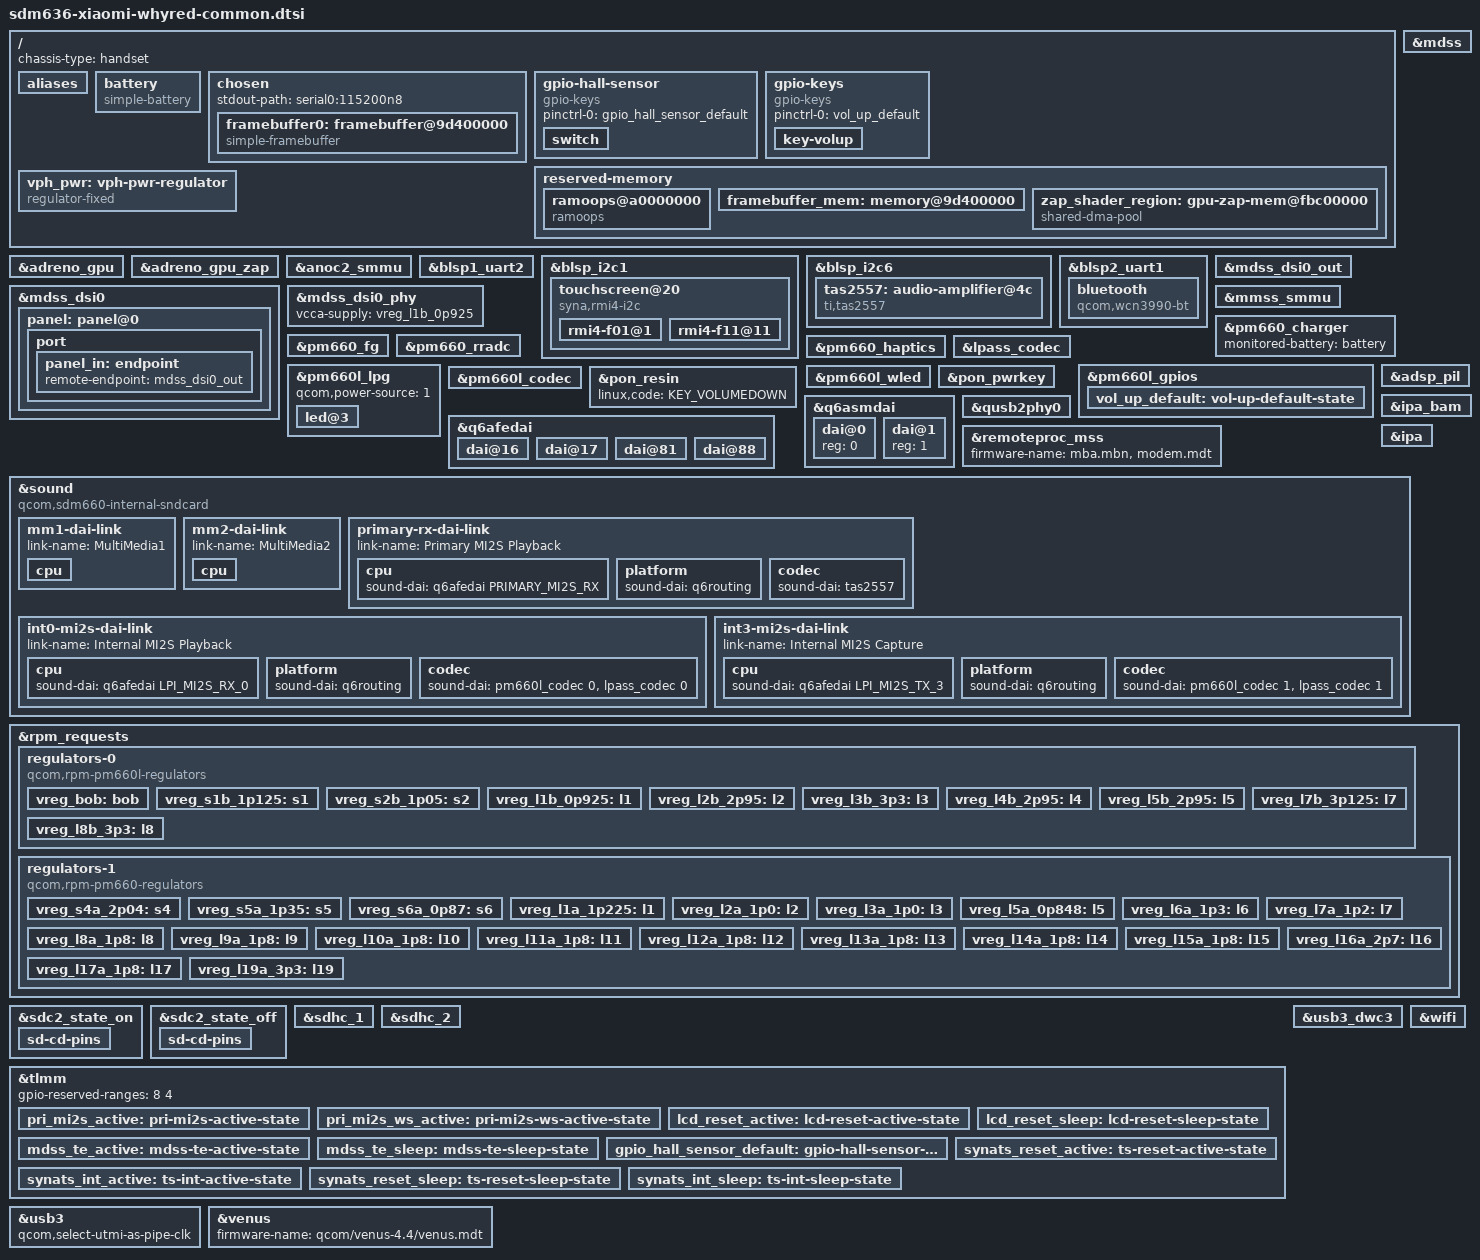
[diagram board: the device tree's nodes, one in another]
// SPDX-License-Identifier: BSD-3-Clause
// SPDX-FileCopyrightText: 2025 Mathesh Velayudan <123v.mathesh@gmail.com>
// SPDX-FileCopyrightText: 2025 Alexey Minnekhanov <alexeymin@postmarketos.org>
// SPDX-FileCopyrightText: 2026 RVC11 <membermadde.insiddev25120@hotmail.com>

/dts-v1/;

#include "sdm636.dtsi"
#include "pm660.dtsi"
#include "pm660l.dtsi"
#include <dt-bindings/gpio/gpio.h>
#include <dt-bindings/input/input.h>
#include <dt-bindings/input/gpio-keys.h>
#include <dt-bindings/leds/common.h>
#include <dt-bindings/pinctrl/qcom,pmic-gpio.h>
#include <dt-bindings/sound/qcom,q6afe.h>
#include <dt-bindings/sound/qcom,q6asm.h>

/delete-node/ &zap_shader_region;

/ {
	chassis-type = "handset";

	aliases {
		serial0 = &blsp1_uart2;
		serial1 = &blsp2_uart1;
	};

	battery: battery {
		compatible = "simple-battery";

		charge-full-design-microamp-hours = <4000000>;
		voltage-min-design-microvolt = <3400000>;
		voltage-max-design-microvolt = <4408000>;
	};

	chosen {
		#address-cells = <2>;
		#size-cells = <2>;
		ranges;

		stdout-path = "serial0:115200n8";

		framebuffer0: framebuffer@9d400000 {
			compatible = "simple-framebuffer";
			reg = <0 0x9d400000 0x0 (1080 * 2160 * 4)>;
			width = <1080>;
			height = <2160>;
			stride = <(1080 * 4)>;
			format = "a8r8g8b8";

			assigned-clocks = <&mmcc MDSS_MDP_CLK>,
				<&mmcc MDSS_VSYNC_CLK>;
			assigned-clock-rates = <300000000>,
				<19200000>;
			clocks = <&mmcc MDSS_AHB_CLK>,
				<&mmcc MDSS_AXI_CLK>,
				<&mmcc MDSS_VSYNC_CLK>,
				<&mmcc MDSS_MDP_CLK>,
				<&mmcc BYTE0_CLK_SRC>,
				<&mmcc PCLK0_CLK_SRC>,
				<&mmcc MDSS_BYTE0_CLK>,
				<&mmcc MDSS_BYTE0_INTF_CLK>,
				<&mmcc MNOC_AHB_CLK>,
				<&mmcc MISC_AHB_CLK>,
				<&mmcc MDSS_PCLK0_CLK>,
				<&mmcc MDSS_ESC0_CLK>;

			power-domains = <&rpmpd SDM660_VDDCX>, <&mmcc MDSS_GDSC>;
		};
	};

	gpio-hall-sensor {
		compatible = "gpio-keys";

		pinctrl-0 = <&gpio_hall_sensor_default>;
		pinctrl-names = "default";

		switch {
			label = "Hall Effect Sensor";
			gpios = <&tlmm 75 GPIO_ACTIVE_LOW>;
			linux,input-type = <EV_SW>;
			linux,code = <SW_LID>;
			linux,can-disable;
			wakeup-source;
		};
	};

	gpio-keys {
		compatible = "gpio-keys";

		pinctrl-0 = <&vol_up_default>;
		pinctrl-names = "default";

		key-volup {
			label = "Volume Up";
			gpios = <&pm660l_gpios 7 GPIO_ACTIVE_LOW>;
			linux,code = <KEY_VOLUMEUP>;
			debounce-interval = <15>;
		};
	};

	reserved-memory {
		#address-cells = <2>;
		#size-cells = <2>;
		ranges;

		ramoops@a0000000 {
			compatible = "ramoops";
			reg = <0x0 0xa0000000 0x0 0x400000>;
			console-size = <0x200000>;
			record-size = <0>;
			ftrace-size = <0>;
			pmsg-size = <0x200000>;
		};

		framebuffer_mem: memory@9d400000 {
			reg = <0x0 0x9d400000 0x0 (1080 * 2160 * 4)>;
			no-map;
		};

		zap_shader_region: gpu-zap-mem@fbc00000 {
			compatible = "shared-dma-pool";
			reg = <0x0 0xfbc00000 0x0 0x2000>;
			no-map;
		};
	};

	vph_pwr: vph-pwr-regulator {
		compatible = "regulator-fixed";
		regulator-name = "vph_pwr";
		regulator-min-microvolt = <3700000>;
		regulator-max-microvolt = <3700000>;

		regulator-always-on;
		regulator-boot-on;
	};
};

&adreno_gpu {
	status = "okay";
};

&adreno_gpu_zap {
	firmware-name = "a512_zap.mbn";
	memory-region = <&zap_shader_region>;
};

&anoc2_smmu {
	status = "okay";
};


&blsp1_uart2 {
	status = "okay";
};

&blsp_i2c1 {
	status = "okay";

	/* Synaptics E753 */
	touchscreen@20 {
		compatible = "syna,rmi4-i2c";
		reg = <0x20>;

		#address-cells = <1>;
		#size-cells = <0>;
		interrupts-extended = <&tlmm 67 IRQ_TYPE_LEVEL_LOW>;

		pinctrl-0 = <&synats_reset_active &synats_int_active>;
		pinctrl-1 = <&synats_int_sleep &synats_reset_sleep>;
		pinctrl-names = "default", "sleep";
		reset-gpios = <&tlmm 66 GPIO_ACTIVE_LOW>;

		vio-supply = <&vreg_l11a_1p8>;

		syna,reset-active-ms = <20>;
		syna,reset-delay-ms = <200>;
		/*
		 * The panel/reset sequencing on whyred settles later than the
		 * first RMI probe attempt in mainline. Delay long enough for the
		 * display path to finish touching the shared reset domain.
		 */
		syna,startup-delay-ms = <2000>;

		rmi4-f01@1 {
			reg = <0x01>;
			syna,nosleep-mode = <1>;
		};

		rmi4-f11@11 {
			reg = <0x11>;
			syna,sensor-type = <1>;
		};
	};
};

&blsp_i2c6 {
	status = "okay";

	tas2557: audio-amplifier@4c {
		compatible = "ti,tas2557";
		reg = <0x4c>;
		#sound-dai-cells = <0>;
		interrupts-extended = <&tlmm 73 IRQ_TYPE_EDGE_RISING>;
		reset-gpios = <&tlmm 77 GPIO_ACTIVE_HIGH>;
		ti,i2s-bits = <16>;
		status = "okay";
	};
};

&blsp2_uart1 {
	status = "okay";

	bluetooth {
		compatible = "qcom,wcn3990-bt";
		vddxo-supply = <&vreg_l9a_1p8>;
		vddrf-supply = <&vreg_l6a_1p3>;
		vddch0-supply = <&vreg_l19a_3p3>;
		vddio-supply = <&vreg_l13a_1p8>;
		max-speed = <3200000>;
	};
};

&mdss {
	status = "okay";
};

&mdss_dsi0 {
	status = "okay";

	#address-cells = <1>;
	#size-cells = <0>;

	vdd-supply = <&vreg_l1b_0p925>;
	vdda-supply = <&vreg_l1a_1p225>;

	panel: panel@0 {
		reg = <0>;

		backlight = <&pm660l_wled>;
		reset-gpios = <&tlmm 53 GPIO_ACTIVE_LOW>;
		vddio-supply = <&vreg_l11a_1p8>;

		pinctrl-0 = <&lcd_reset_active &mdss_te_active>;
		pinctrl-1 = <&lcd_reset_sleep &mdss_te_sleep>;
		pinctrl-names = "default", "sleep";

		width-mm = <68>;
		height-mm = <136>;

		port {
			panel_in: endpoint {
				remote-endpoint = <&mdss_dsi0_out>;
			};
		};
	};
};

&mdss_dsi0_out {
	data-lanes = <0 1 2 3>;
	remote-endpoint = <&panel_in>;
};

&mdss_dsi0_phy {
	vcca-supply = <&vreg_l1b_0p925>;

	status = "okay";
};

&mmss_smmu {
	status = "okay";
};

&pm660_charger {
	monitored-battery = <&battery>;

	status = "okay";
};

&pm660_fg {
	monitored-battery = <&battery>;
	power-supplies = <&pm660_charger>;

	status = "okay";
};

&pm660_haptics {
	status = "okay";
};

&pm660_rradc {
	status = "okay";
};

&lpass_codec {
	status = "okay";
};

&pm660l_gpios {
	vol_up_default: vol-up-default-state {
		pins = "gpio7";
		function = PMIC_GPIO_FUNC_NORMAL;
		bias-pull-up;
		input-enable;
		qcom,drive-strength = <PMIC_GPIO_STRENGTH_NO>;
	};
};

&pm660l_lpg {
	#address-cells = <1>;
	#size-cells = <0>;
	qcom,power-source = <1>;

	status = "okay";

	led@3 {
		reg = <3>;
		color = <LED_COLOR_ID_WHITE>;
		function = LED_FUNCTION_STATUS;
	};
};

&pm660l_wled {
	qcom,switching-freq = <800>;
	qcom,current-limit-microamp = <20000>;
	qcom,num-strings = <2>;

	status = "okay";
};

&pm660l_codec {
	vdd-cdc-io-supply = <&vreg_s4a_2p04>;
	vdd-cdc-tx-rx-cx-supply = <&vreg_s4a_2p04>;
	vdd-micbias-supply = <&vreg_l7b_3p125>;

	qcom,micbias-lvl = <2600>;
	qcom,micbias1-ext-cap;

	status = "okay";
};

&pon_pwrkey {
	status = "okay";
};

&pon_resin {
	linux,code = <KEY_VOLUMEDOWN>;

	status = "okay";
};

&q6afedai {
	dai@16 {
		reg = <PRIMARY_MI2S_RX>;
		qcom,sd-lines = <0>;
	};

	dai@17 {
		reg = <PRIMARY_MI2S_TX>;
		qcom,sd-lines = <0>;
	};

	dai@81 {
		reg = <LPI_MI2S_RX_0>;
		qcom,sd-lines = <0 1>;
	};

	dai@88 {
		reg = <LPI_MI2S_TX_3>;
		qcom,sd-lines = <0 1>;
	};
};

&q6asmdai {
	dai@0 {
		reg = <0>;
	};

	dai@1 {
		reg = <1>;
	};
};

&qusb2phy0 {
	vdd-supply = <&vreg_l1b_0p925>;
	vdda-pll-supply = <&vreg_l10a_1p8>;
	vdda-phy-dpdm-supply = <&vreg_l7b_3p125>;

	status = "okay";
};

/*
 * Modem firmware (mba.mbn, modem.*) is read from the stock modem partition at
 * boot by msm-firmware-loader; do not ship or stub these in the rootfs.
 */
&remoteproc_mss {
	firmware-name = "mba.mbn", "modem.mdt";

	status = "okay";
};

&adsp_pil {
	status = "okay";
};

&ipa_bam {
	status = "okay";
};

&ipa {
	status = "okay";
};

&sound {
	compatible = "qcom,sdm660-internal-sndcard";
	model = "Xiaomi Redmi Note 5 Pro";

	pinctrl-0 = <&cdc_pdm_default>,
			<&cdc_dmic_default>,
			<&pri_mi2s_active>,
			<&pri_mi2s_ws_active>;
	pinctrl-names = "default";

	audio-routing = "PDM_RX1", "Digital PDM_RX1",
			"RX_BIAS", "Digital MCLK",
			"INT_LDO_H", "Digital MCLK",
			"Digital RX_I2S_CLK", "Digital MCLK",
			"Digital TX_I2S_CLK", "Digital MCLK",
			"Digital ADC1", "ADC1",
			"Digital ADC2", "ADC2",
			"Digital ADC3", "ADC3",
			"PDM_RX2", "Digital PDM_RX2",
			"PDM_RX3", "Digital PDM_RX3",
			"Digital LPASS_PDM_TX", "PDM_TX",
			"AMIC1", "MIC BIAS External1",
			"AMIC2", "MIC BIAS External2";

	mm1-dai-link {
		link-name = "MultiMedia1";

		cpu {
			sound-dai = <&q6asmdai MSM_FRONTEND_DAI_MULTIMEDIA1>;
		};
	};

	mm2-dai-link {
		link-name = "MultiMedia2";

		cpu {
			sound-dai = <&q6asmdai MSM_FRONTEND_DAI_MULTIMEDIA2>;
		};
	};

	primary-rx-dai-link {
		link-name = "Primary MI2S Playback";

		cpu {
			sound-dai = <&q6afedai PRIMARY_MI2S_RX>;
		};

		platform {
			sound-dai = <&q6routing>;
		};

		codec {
			sound-dai = <&tas2557>;
		};
	};

	int0-mi2s-dai-link {
		link-name = "Internal MI2S Playback";

		cpu {
			sound-dai = <&q6afedai LPI_MI2S_RX_0>;
		};

		platform {
			sound-dai = <&q6routing>;
		};

		codec {
			sound-dai = <&pm660l_codec 0>,
					<&lpass_codec 0>;
		};
	};

	int3-mi2s-dai-link {
		link-name = "Internal MI2S Capture";

		cpu {
			sound-dai = <&q6afedai LPI_MI2S_TX_3>;
		};

		platform {
			sound-dai = <&q6routing>;
		};

		codec {
			sound-dai = <&pm660l_codec 1>,
					<&lpass_codec 1>;
		};
	};
};

&rpm_requests {
	regulators-0 {
		compatible = "qcom,rpm-pm660l-regulators";

		vdd_s1-supply = <&vph_pwr>;
		vdd_s2-supply = <&vph_pwr>;
		vdd_s3_s4-supply = <&vph_pwr>;
		vdd_s5-supply = <&vph_pwr>;
		vdd_s6-supply = <&vph_pwr>;

		vdd_l1_l9_l10-supply = <&vreg_s2b_1p05>;
		vdd_l2-supply = <&vreg_bob>;
		vdd_l3_l5_l7_l8-supply = <&vreg_bob>;
		vdd_l4_l6-supply = <&vreg_bob>;
		vdd_bob-supply = <&vph_pwr>;

		vreg_bob: bob {
			regulator-min-microvolt = <3300000>;
			regulator-max-microvolt = <3600000>;
			regulator-enable-ramp-delay = <500>;
		};

		vreg_s1b_1p125: s1 {
			regulator-min-microvolt = <1125000>;
			regulator-max-microvolt = <1125000>;
			regulator-enable-ramp-delay = <200>;
		};

		vreg_s2b_1p05: s2 {
			regulator-min-microvolt = <1050000>;
			regulator-max-microvolt = <1050000>;
			regulator-enable-ramp-delay = <200>;
		};

		/* LDOs */
		vreg_l1b_0p925: l1 {
			regulator-min-microvolt = <800000>;
			regulator-max-microvolt = <925000>;
			regulator-enable-ramp-delay = <250>;
			regulator-allow-set-load;
		};

		/* SDHCI 3.3V signal doesn't seem to be supported. */
		vreg_l2b_2p95: l2 {
			regulator-min-microvolt = <1648000>;
			regulator-max-microvolt = <3100000>;
			regulator-enable-ramp-delay = <250>;
			regulator-allow-set-load;
		};

		vreg_l3b_3p3: l3 {
			regulator-min-microvolt = <1710000>;
			regulator-max-microvolt = <3600000>;
			regulator-enable-ramp-delay = <250>;
			regulator-allow-set-load;
			regulator-always-on;
		};

		vreg_l4b_2p95: l4 {
			regulator-min-microvolt = <1700000>;
			regulator-max-microvolt = <2950000>;
			regulator-enable-ramp-delay = <250>;

			regulator-min-microamp = <200>;
			regulator-max-microamp = <600000>;
			regulator-system-load = <570000>;
			regulator-allow-set-load;
		};

		/*
		 * Downstream specifies a range of 1721-3600mV,
		 * but the only assigned consumers are SDHCI2 VMMC
		 * and Coresight QPDI that both request pinned 2.95V.
		 * Tighten the range to 1.8-3.328 (closest to 3.3) to
		 * make the mmc driver happy.
		 */
		vreg_l5b_2p95: l5 {
			regulator-min-microvolt = <1800000>;
			regulator-max-microvolt = <3328000>;
			regulator-enable-ramp-delay = <250>;
			regulator-allow-set-load;
			regulator-system-load = <800000>;
		};

		vreg_l7b_3p125: l7 {
			regulator-min-microvolt = <2700000>;
			regulator-max-microvolt = <3125000>;
			regulator-enable-ramp-delay = <250>;
		};

		vreg_l8b_3p3: l8 {
			regulator-min-microvolt = <3200000>;
			regulator-max-microvolt = <3400000>;
			regulator-enable-ramp-delay = <250>;
		};
	};

	regulators-1 {
		compatible = "qcom,rpm-pm660-regulators";

		vdd_s1-supply = <&vph_pwr>;
		vdd_s2-supply = <&vph_pwr>;
		vdd_s3-supply = <&vph_pwr>;
		vdd_s4-supply = <&vph_pwr>;
		vdd_s5-supply = <&vph_pwr>;
		vdd_s6-supply = <&vph_pwr>;

		vdd_l1_l6_l7-supply = <&vreg_s5a_1p35>;
		vdd_l2_l3-supply = <&vreg_s2b_1p05>;
		vdd_l5-supply = <&vreg_s2b_1p05>;
		vdd_l8_l9_l10_l11_l12_l13_l14-supply = <&vreg_s4a_2p04>;
		vdd_l15_l16_l17_l18_l19-supply = <&vreg_bob>;

		/*
		 * S1A (FTAPC0), S2A (FTAPC1), S3A (HFAPC1) are managed
		 * by the Core Power Reduction hardened (CPRh) and the
		 * Operating State Manager (OSM) HW automatically.
		 */

		vreg_s4a_2p04: s4 {
			regulator-min-microvolt = <1805000>;
			regulator-max-microvolt = <2040000>;
			regulator-enable-ramp-delay = <200>;
			regulator-always-on;
		};

		vreg_s5a_1p35: s5 {
			regulator-min-microvolt = <1224000>;
			regulator-max-microvolt = <1350000>;
			regulator-enable-ramp-delay = <200>;
		};

		vreg_s6a_0p87: s6 {
			regulator-min-microvolt = <504000>;
			regulator-max-microvolt = <992000>;
			regulator-enable-ramp-delay = <150>;
		};

		/* LDOs */
		vreg_l1a_1p225: l1 {
			regulator-min-microvolt = <1150000>;
			regulator-max-microvolt = <1250000>;
			regulator-enable-ramp-delay = <250>;
			regulator-allow-set-load;
		};

		vreg_l2a_1p0: l2 {
			regulator-min-microvolt = <950000>;
			regulator-max-microvolt = <1010000>;
			regulator-enable-ramp-delay = <250>;
		};

		vreg_l3a_1p0: l3 {
			regulator-min-microvolt = <950000>;
			regulator-max-microvolt = <1010000>;
			regulator-enable-ramp-delay = <250>;
		};

		vreg_l5a_0p848: l5 {
			regulator-min-microvolt = <525000>;
			regulator-max-microvolt = <950000>;
			regulator-enable-ramp-delay = <250>;
		};

		vreg_l6a_1p3: l6 {
			regulator-min-microvolt = <1200000>;
			regulator-max-microvolt = <1370000>;
			regulator-allow-set-load;
			regulator-enable-ramp-delay = <250>;
		};

		vreg_l7a_1p2: l7 {
			regulator-min-microvolt = <1200000>;
			regulator-max-microvolt = <1200000>;
			regulator-enable-ramp-delay = <250>;
		};

		vreg_l8a_1p8: l8 {
			regulator-min-microvolt = <1750000>;
			regulator-max-microvolt = <1900000>;
			regulator-enable-ramp-delay = <250>;
			regulator-system-load = <325000>;
			regulator-allow-set-load;
		};

		vreg_l9a_1p8: l9 {
			regulator-min-microvolt = <1750000>;
			regulator-max-microvolt = <1900000>;
			regulator-enable-ramp-delay = <250>;
			regulator-allow-set-load;
		};

		vreg_l10a_1p8: l10 {
			regulator-min-microvolt = <1780000>;
			regulator-max-microvolt = <1950000>;
			regulator-enable-ramp-delay = <250>;
			regulator-allow-set-load;
			regulator-system-load = <14000>;
		};

		vreg_l11a_1p8: l11 {
			regulator-min-microvolt = <1780000>;
			regulator-max-microvolt = <1950000>;
			regulator-enable-ramp-delay = <250>;
		};

		vreg_l12a_1p8: l12 {
			regulator-min-microvolt = <1780000>;
			regulator-max-microvolt = <1950000>;
			regulator-enable-ramp-delay = <250>;
		};

		/* This gives power to the LPDDR4: never turn it off! */
		vreg_l13a_1p8: l13 {
			regulator-min-microvolt = <1780000>;
			regulator-max-microvolt = <1950000>;
			regulator-enable-ramp-delay = <250>;
			regulator-boot-on;
			regulator-always-on;
		};

		vreg_l14a_1p8: l14 {
			regulator-min-microvolt = <1710000>;
			regulator-max-microvolt = <1900000>;
			regulator-enable-ramp-delay = <250>;
		};

		vreg_l15a_1p8: l15 {
			regulator-min-microvolt = <1650000>;
			regulator-max-microvolt = <2950000>;
			regulator-enable-ramp-delay = <250>;
		};

		vreg_l16a_2p7: l16 {
			regulator-min-microvolt = <2800000>;
			regulator-max-microvolt = <2800000>;
			regulator-enable-ramp-delay = <250>;
			regulator-always-on;
		};

		vreg_l17a_1p8: l17 {
			regulator-min-microvolt = <1650000>;
			regulator-max-microvolt = <2950000>;
			regulator-enable-ramp-delay = <250>;
		};

		vreg_l19a_3p3: l19 {
			regulator-min-microvolt = <3200000>;
			regulator-max-microvolt = <3400000>;
			regulator-enable-ramp-delay = <250>;
			regulator-allow-set-load;
		};
	};
};

&sdc2_state_on {
	sd-cd-pins {
		pins = "gpio54";
		function = "gpio";
		bias-pull-up;
		drive-strength = <2>;
	};
};

&sdc2_state_off {
	sd-cd-pins {
		pins = "gpio54";
		function = "gpio";
		bias-disable;
		drive-strength = <2>;
	};
};

&sdhc_1 {
	supports-cqe;

	mmc-hs200-1_8v;
	mmc-hs400-1_8v;
	mmc-hs400-enhanced-strobe;

	vmmc-supply = <&vreg_l4b_2p95>;
	vqmmc-supply = <&vreg_l8a_1p8>;

	status = "okay";
};

&sdhc_2 {
	cd-gpios = <&tlmm 54 GPIO_ACTIVE_HIGH>;
	vmmc-supply = <&vreg_l5b_2p95>;
	vqmmc-supply = <&vreg_l2b_2p95>;

	status = "okay";
};

&tlmm {
	gpio-reserved-ranges = <8 4>;

	pri_mi2s_active: pri-mi2s-active-state {
		pins = "gpio12", "gpio14", "gpio15";
		function = "pri_mi2s";
		drive-strength = <8>;
		bias-disable;
	};

	pri_mi2s_ws_active: pri-mi2s-ws-active-state {
		pins = "gpio13";
		function = "pri_mi2s_ws";
		drive-strength = <8>;
		bias-disable;
	};

	lcd_reset_active: lcd-reset-active-state {
		function = "gpio";
		pins = "gpio53";
		drive-strength = <8>;
		bias-disable;
	};

	lcd_reset_sleep: lcd-reset-sleep-state {
		pins = "gpio53";
		function = "gpio";
		drive-strength = <2>;
		bias-pull-down;
	};

	mdss_te_active: mdss-te-active-state {
		pins = "gpio59";
		function = "mdp_vsync";
		drive-strength = <2>;
		bias-pull-down;
	};

	mdss_te_sleep: mdss-te-sleep-state {
		pins = "gpio59";
		function = "mdp_vsync";
		drive-strength = <2>;
		bias-pull-down;
	};

	gpio_hall_sensor_default: gpio-hall-sensor-default-state {
		pins = "gpio75";
		function = "gpio";
		drive-strength = <6>;
		bias-pull-up;
	};

	synats_reset_active: ts-reset-active-state {
		pins = "gpio66";
		function = "gpio";
		drive-strength = <16>;
		bias-pull-up;
	};

	synats_int_active: ts-int-active-state {
		pins = "gpio67";
		function = "gpio";
		drive-strength = <2>;
		bias-pull-up;
	};

	synats_reset_sleep: ts-reset-sleep-state {
		pins = "gpio66";
		function = "gpio";
		drive-strength = <2>;
		bias-pull-down;
	};

	synats_int_sleep: ts-int-sleep-state {
		pins = "gpio67";
		function = "gpio";
		drive-strength = <2>;
		bias-disable;
	};
};

&usb3 {
	qcom,select-utmi-as-pipe-clk;

	status = "okay";
};

&usb3_dwc3 {
	maximum-speed = "high-speed";
	phys = <&qusb2phy0>;
	phy-names = "usb2-phy";
	dr_mode = "peripheral";

	status = "okay";
};

&venus {
	firmware-name = "qcom/venus-4.4/venus.mdt";

	status = "okay";
};

&wifi {
	vdd-0.8-cx-mx-supply = <&vreg_l5a_0p848>;
	vdd-1.8-xo-supply = <&vreg_l9a_1p8>;
	vdd-1.3-rfa-supply = <&vreg_l6a_1p3>;
	vdd-3.3-ch0-supply = <&vreg_l19a_3p3>;
	vdd-3.3-ch1-supply = <&vreg_l19a_3p3>;

	status = "okay";
};
